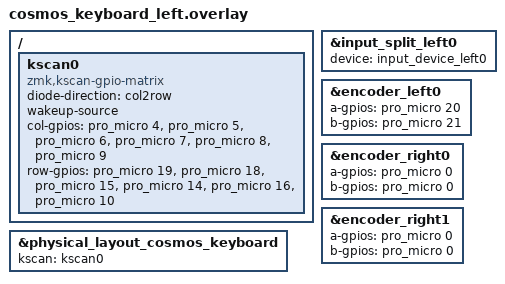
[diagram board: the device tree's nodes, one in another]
#include "cosmos_keyboard.dtsi"

/ {
    kscan0: kscan0 {
        compatible = "zmk,kscan-gpio-matrix";
                diode-direction = "col2row";
        wakeup-source;

        col-gpios
            = <&pro_micro 4 GPIO_ACTIVE_HIGH>
            , <&pro_micro 5 GPIO_ACTIVE_HIGH>
            , <&pro_micro 6 GPIO_ACTIVE_HIGH>
            , <&pro_micro 7 GPIO_ACTIVE_HIGH>
            , <&pro_micro 8 GPIO_ACTIVE_HIGH>
            , <&pro_micro 9 GPIO_ACTIVE_HIGH>
            ;

        row-gpios
            = <&pro_micro 19 (GPIO_ACTIVE_HIGH | GPIO_PULL_DOWN)>
            , <&pro_micro 18 (GPIO_ACTIVE_HIGH | GPIO_PULL_DOWN)>
            , <&pro_micro 15 (GPIO_ACTIVE_HIGH | GPIO_PULL_DOWN)>
            , <&pro_micro 14 (GPIO_ACTIVE_HIGH | GPIO_PULL_DOWN)>
            , <&pro_micro 16 (GPIO_ACTIVE_HIGH | GPIO_PULL_DOWN)>
            , <&pro_micro 10 (GPIO_ACTIVE_HIGH | GPIO_PULL_DOWN)>
            ;
    };
};

&physical_layout_cosmos_keyboard {
    kscan = <&kscan0>;
};
// == Input devices ==
// Peripheral half: ZMK gates input listeners behind ZMK_SPLIT_ROLE_CENTRAL, so
// the trackball is exposed over the split link and the listener lives on the right.
&input_split_left0 {
    status = "okay";
    device = <&input_device_left0>;
};

&encoder_left0 {
    a-gpios = <&pro_micro 20 (GPIO_ACTIVE_HIGH | GPIO_PULL_UP)>;
    b-gpios = <&pro_micro 21 (GPIO_ACTIVE_HIGH | GPIO_PULL_UP)>;
    status = "okay";
};

// Dummy pins for the other part's encoders, to satisfy devicetree. These nodes
// stay disabled, so nothing is compiled for them.
&encoder_right0 {
    a-gpios = <&pro_micro 0 (GPIO_ACTIVE_HIGH | GPIO_PULL_UP)>;
    b-gpios = <&pro_micro 0 (GPIO_ACTIVE_HIGH | GPIO_PULL_UP)>;
};
&encoder_right1 {
    a-gpios = <&pro_micro 0 (GPIO_ACTIVE_HIGH | GPIO_PULL_UP)>;
    b-gpios = <&pro_micro 0 (GPIO_ACTIVE_HIGH | GPIO_PULL_UP)>;
};
